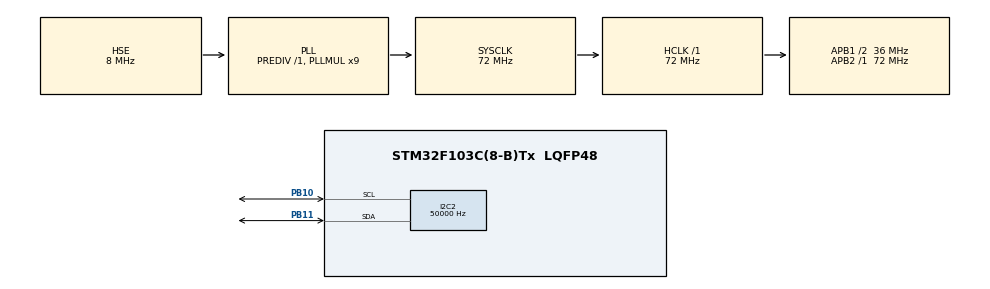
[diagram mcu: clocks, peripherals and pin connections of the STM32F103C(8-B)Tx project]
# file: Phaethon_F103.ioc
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FREERTOS.Tasks01=defaultTask,24,128,StartDefaultTask,Default,NULL,Dynamic,NULL,NULL
FREERTOS.configTOTAL_HEAP_SIZE=1024
I2C2.ClockSpeed=50000
Mcu.Family=STM32F1
Mcu.Name=STM32F103C(8-B)Tx
Mcu.Package=LQFP48
NVIC.PriorityGroup=NVIC_PRIORITYGROUP_4
PA13.Mode=Serial_Wire
PA13.Signal=SYS_JTMS-SWDIO
PA14.Mode=Serial_Wire
PA14.Signal=SYS_JTCK-SWCLK
PB10.Mode=I2C
PB10.Signal=I2C2_SCL
PB11.Mode=I2C
PB11.Signal=I2C2_SDA
PC14-OSC32_IN.Mode=LSE-External-Oscillator
PC14-OSC32_IN.Signal=RCC_OSC32_IN
PC15-OSC32_OUT.Mode=LSE-External-Oscillator
PC15-OSC32_OUT.Signal=RCC_OSC32_OUT
PD0-OSC_IN.Mode=HSE-External-Oscillator
PD0-OSC_IN.Signal=RCC_OSC_IN
PD1-OSC_OUT.Mode=HSE-External-Oscillator
PD1-OSC_OUT.Signal=RCC_OSC_OUT
ProjectManager.HeapSize=0x200
ProjectManager.StackSize=0x400
ProjectManager.TargetToolchain=STM32CubeIDE
RCC.AHBFreq_Value=72000000
RCC.APB1CLKDivider=RCC_HCLK_DIV2
RCC.APB1Freq_Value=36000000
RCC.APB1TimFreq_Value=72000000
RCC.APB2Freq_Value=72000000
RCC.APB2TimFreq_Value=72000000
RCC.EnbaleCSS=true
RCC.HCLKFreq_Value=72000000
RCC.PLLMUL=RCC_PLL_MUL9
RCC.PLLSourceVirtual=RCC_PLLSOURCE_HSE
RCC.RTCClockSelection=RCC_RTCCLKSOURCE_LSE
RCC.SYSCLKFreq_VALUE=72000000
RCC.SYSCLKSource=RCC_SYSCLKSOURCE_PLLCLK
RCC.USBFreq_Value=72000000
VP_FREERTOS_VS_CMSIS_V2.Mode=CMSIS_V2
VP_RTC_VS_RTC_Activate.Mode=RTC_Enabled
VP_RTC_VS_RTC_Calendar.Mode=RTC_Calendar
board=custom

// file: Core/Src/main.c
/* USER CODE BEGIN Header */
/**
  ******************************************************************************
  * @file           : main.c
  * @brief          : Main program body
  ******************************************************************************
  * @attention
  *
  * <h2><center>&copy; Copyright (c) 2019 STMicroelectronics.
  * All rights reserved.</center></h2>
  *
  * This software component is licensed by ST under BSD 3-Clause license,
  * the "License"; You may not use this file except in compliance with the
  * License. You may obtain a copy of the License at:
  *                        opensource.org/licenses/BSD-3-Clause
  *
  ******************************************************************************
  */
/* USER CODE END Header */

#include "main.h"
#include "cmsis_os.h"

/* USER CODE BEGIN Includes */
#include"ssd1306.h"
/* USER CODE END Includes */

I2C_HandleTypeDef hi2c2;

RTC_HandleTypeDef hrtc;

osThreadId_t defaultTaskHandle;

void SystemClock_Config(void);
static void MX_GPIO_Init(void);
static void MX_I2C2_Init(void);
static void MX_RTC_Init(void);
void StartDefaultTask(void *argument);

int main(void)
{

  /* MCU Configuration--------------------------------------------------------*/

  /* Reset of all peripherals, Initializes the Flash interface and the Systick. */
  HAL_Init();

  /* Configure the system clock */
  SystemClock_Config();

  /* Initialize all configured peripherals */
  MX_GPIO_Init();
  MX_I2C2_Init();
  MX_RTC_Init();
  /* USER CODE BEGIN 2 */
  ssd1306_Init();
  test();
/*  ssd1306_Fill(White);
  ssd1306_UpdateScreen();
  ssd1306_SetCursor(23,23);
  ssd1306_WriteString("4ilo",Font_11x18,White);
  ssd1306_UpdateScreen();*/
  /* USER CODE END 2 */

  osKernelInitialize();

  /* Create the thread(s) */
  /* definition and creation of defaultTask */
  const osThreadAttr_t defaultTask_attributes = {
    .name = "defaultTask",
    .priority = (osPriority_t) osPriorityNormal,
    .stack_size = 128
  };
  defaultTaskHandle = osThreadNew(StartDefaultTask, NULL, &defaultTask_attributes);

  /* Start scheduler */
  osKernelStart();

  /* We should never get here as control is now taken by the scheduler */

  /* Infinite loop */
  while (1)
  {

  }
}

void SystemClock_Config(void)
{
  RCC_OscInitTypeDef RCC_OscInitStruct = {0};
  RCC_ClkInitTypeDef RCC_ClkInitStruct = {0};
  RCC_PeriphCLKInitTypeDef PeriphClkInit = {0};

  /** Initializes the CPU, AHB and APB busses clocks
  */
  RCC_OscInitStruct.OscillatorType = RCC_OSCILLATORTYPE_HSE|RCC_OSCILLATORTYPE_LSE;
  RCC_OscInitStruct.HSEState = RCC_HSE_ON;
  RCC_OscInitStruct.HSEPredivValue = RCC_HSE_PREDIV_DIV1;
  RCC_OscInitStruct.LSEState = RCC_LSE_ON;
  RCC_OscInitStruct.HSIState = RCC_HSI_ON;
  RCC_OscInitStruct.PLL.PLLState = RCC_PLL_ON;
  RCC_OscInitStruct.PLL.PLLSource = RCC_PLLSOURCE_HSE;
  RCC_OscInitStruct.PLL.PLLMUL = RCC_PLL_MUL9;
  if (HAL_RCC_OscConfig(&RCC_OscInitStruct) != HAL_OK)
  {
    Error_Handler();
  }
  /** Initializes the CPU, AHB and APB busses clocks
  */
  RCC_ClkInitStruct.ClockType = RCC_CLOCKTYPE_HCLK|RCC_CLOCKTYPE_SYSCLK
                              |RCC_CLOCKTYPE_PCLK1|RCC_CLOCKTYPE_PCLK2;
  RCC_ClkInitStruct.SYSCLKSource = RCC_SYSCLKSOURCE_PLLCLK;
  RCC_ClkInitStruct.AHBCLKDivider = RCC_SYSCLK_DIV1;
  RCC_ClkInitStruct.APB1CLKDivider = RCC_HCLK_DIV2;
  RCC_ClkInitStruct.APB2CLKDivider = RCC_HCLK_DIV1;

  if (HAL_RCC_ClockConfig(&RCC_ClkInitStruct, FLASH_LATENCY_2) != HAL_OK)
  {
    Error_Handler();
  }
  PeriphClkInit.PeriphClockSelection = RCC_PERIPHCLK_RTC;
  PeriphClkInit.RTCClockSelection = RCC_RTCCLKSOURCE_LSE;
  if (HAL_RCCEx_PeriphCLKConfig(&PeriphClkInit) != HAL_OK)
  {
    Error_Handler();
  }
  /** Enables the Clock Security System
  */
  HAL_RCC_EnableCSS();
}

static void MX_I2C2_Init(void)
{

  hi2c2.Instance = I2C2;
  hi2c2.Init.ClockSpeed = 200000;
  hi2c2.Init.DutyCycle = I2C_DUTYCYCLE_2;
  hi2c2.Init.OwnAddress1 = 0xA2;
  hi2c2.Init.AddressingMode = I2C_ADDRESSINGMODE_7BIT;
  hi2c2.Init.DualAddressMode = I2C_DUALADDRESS_DISABLE;
  hi2c2.Init.OwnAddress2 = 0xA3;
  hi2c2.Init.GeneralCallMode = I2C_GENERALCALL_DISABLE;
  hi2c2.Init.NoStretchMode = I2C_NOSTRETCH_DISABLE;
  if (HAL_I2C_Init(&hi2c2) != HAL_OK)
  {
    Error_Handler();
  }

}

static void MX_RTC_Init(void)
{

  RTC_TimeTypeDef sTime = {0};
  RTC_DateTypeDef DateToUpdate = {0};

  /** Initialize RTC Only
  */
  hrtc.Instance = RTC;
  hrtc.Init.AsynchPrediv = RTC_AUTO_1_SECOND;
  hrtc.Init.OutPut = RTC_OUTPUTSOURCE_ALARM;
  if (HAL_RTC_Init(&hrtc) != HAL_OK)
  {
    Error_Handler();
  }

  /** Initialize RTC and set the Time and Date
  */
  sTime.Hours = 0x0;
  sTime.Minutes = 0x0;
  sTime.Seconds = 0x0;

  if (HAL_RTC_SetTime(&hrtc, &sTime, RTC_FORMAT_BCD) != HAL_OK)
  {
    Error_Handler();
  }
  DateToUpdate.WeekDay = RTC_WEEKDAY_MONDAY;
  DateToUpdate.Month = RTC_MONTH_JANUARY;
  DateToUpdate.Date = 0x1;
  DateToUpdate.Year = 0x0;

  if (HAL_RTC_SetDate(&hrtc, &DateToUpdate, RTC_FORMAT_BCD) != HAL_OK)
  {
    Error_Handler();
  }

}

static void MX_GPIO_Init(void)
{

  /* GPIO Ports Clock Enable */
  __HAL_RCC_GPIOC_CLK_ENABLE();
  __HAL_RCC_GPIOD_CLK_ENABLE();
  __HAL_RCC_GPIOB_CLK_ENABLE();
  __HAL_RCC_GPIOA_CLK_ENABLE();

}

void StartDefaultTask(void *argument)
{
  for(;;)
  {
    osDelay(1);
  }
}

void Error_Handler(void)
{
}

/************************ (C) COPYRIGHT STMicroelectronics *****END OF FILE****/
